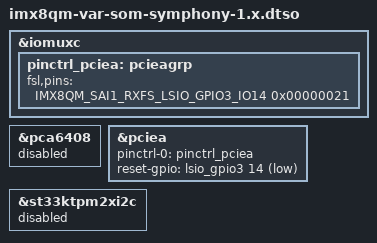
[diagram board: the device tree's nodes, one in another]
// SPDX-License-Identifier: (GPL-2.0+ OR MIT)
/*
 * Device tree overlay to support the VAR-SOM-MX8 on Symphony Board 1.x
 *
 * Copyright 2025 Variscite Ltd.
 */

/dts-v1/;
/plugin/;

#include <dt-bindings/gpio/gpio.h>
#include <dt-bindings/pinctrl/pads-imx8qm.h>

&iomuxc {
	pinctrl_pciea: pcieagrp {
		fsl,pins = <
			IMX8QM_SAI1_RXFS_LSIO_GPIO3_IO14			0x00000021
		>;
	};
};

&pca6408 {
	status = "disabled";
};

&pciea{
	pinctrl-names = "default";
	pinctrl-0 = <&pinctrl_pciea>;
	reset-gpio = <&lsio_gpio3 14 GPIO_ACTIVE_LOW>;
};

&st33ktpm2xi2c {
	status = "disabled";
};
